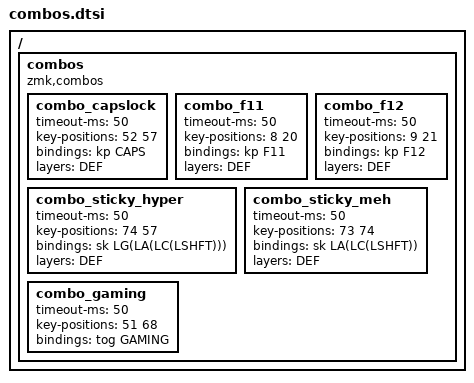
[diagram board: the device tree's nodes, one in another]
/*                KEY POSITIONS — Glove80

  See TailorKey POS_* defines for reference:
  LH_T1=52 LH_T2=53 LH_T3=54        RH_T3=55 RH_T2=56 RH_T1=57
  LH_T4=69 LH_T5=70 LH_T6=71        RH_T6=72 RH_T5=73 RH_T4=74
  LH_C1R5=51 LH_C2R6=68
  RH_C5R1=8 RH_C5R2=20 RH_C6R1=9 RH_C6R2=21                      */

/ {
    combos {
        compatible = "zmk,combos";

        /* CapsLock: both inner thumb keys */
        combo_capslock {
            timeout-ms = <50>;
            key-positions = <52 57>;
            bindings = <&kp CAPS>;
            layers = <DEF>;
        };

        /* F11: right C5 R1+R2 */
        combo_f11 {
            timeout-ms = <50>;
            key-positions = <8 20>;
            bindings = <&kp F11>;
            layers = <DEF>;
        };

        /* F12: right C6 R1+R2 */
        combo_f12 {
            timeout-ms = <50>;
            key-positions = <9 21>;
            bindings = <&kp F12>;
            layers = <DEF>;
        };

        /* Sticky Hyper (Win+Alt+Ctrl+Shift): RH_T4 + RH_T1 */
        combo_sticky_hyper {
            timeout-ms = <50>;
            key-positions = <74 57>;
            bindings = <&sk LG(LA(LC(LSHFT)))>;
            layers = <DEF>;
        };

        /* Sticky Meh (Alt+Ctrl+Shift): RH_T5 + RH_T4 */
        combo_sticky_meh {
            timeout-ms = <50>;
            key-positions = <73 74>;
            bindings = <&sk LA(LC(LSHFT))>;
            layers = <DEF>;
        };

        /* Toggle Gaming layer: LH_C1R5 + LH_C2R6 */
        combo_gaming {
            timeout-ms = <50>;
            key-positions = <51 68>;
            bindings = <&tog GAMING>;
        };
    };
};

/* ==========================================================================
 * UROB'S ORIGINAL COMBOS — preserved for reference.
 *
 * Urob's combos provided symbols without a symbol layer:
 *
 * Horizontal combos (left hand):
 *   W+F = Esc, F+P = smart mouse, R+S = Tab (with HRM), S+T = leader,
 *   R+S+T = leader+shift, X+D = cut, X+C = copy, C+D = paste
 *
 * Horizontal combos (right hand):
 *   L+U = Bspc, U+Y = Del, N+E = ( (with HRM), E+I = ) (with HRM),
 *   H+,  = [, ,+. = ]
 *
 * Vertical combos (left hand):
 *   W+R = @, F+S = #, P+T = $, B+G = %
 *   R+X = `, S+C = \, T+D = =, G+V = ~
 *
 * Vertical combos (right hand):
 *   M+J = ^, L+N = +, U+E = *, Y+I = &
 *   J+K = _, N+H = -, E+, = /, I+. = |
 *
 * These use ZMK_COMBO macros from zmk-helpers. The 8-arg version
 * (ZMK_COMBO_8) creates HRM-aware combos that can chord with mods.
 * See git history for the full original combos.dtsi.
 * ========================================================================== */
